# Display_Subsystem register map
Vendor: Texas Instruments
Peripheral module from a debugger description file (folder omap34xx).
Registers are 32-bit, read-only, reset 0x0 unless marked. A register's access mark holds for its fields unless they carry their own. Offsets are as the file gives them; lines under a group give offsets from that group; [hi:lo] are bit positions; {n}, {i} and the like mark numbered series; 'fields as' and 'values as' point back to an identical list; <NAME> marks a mode.

## Display_Subsystem
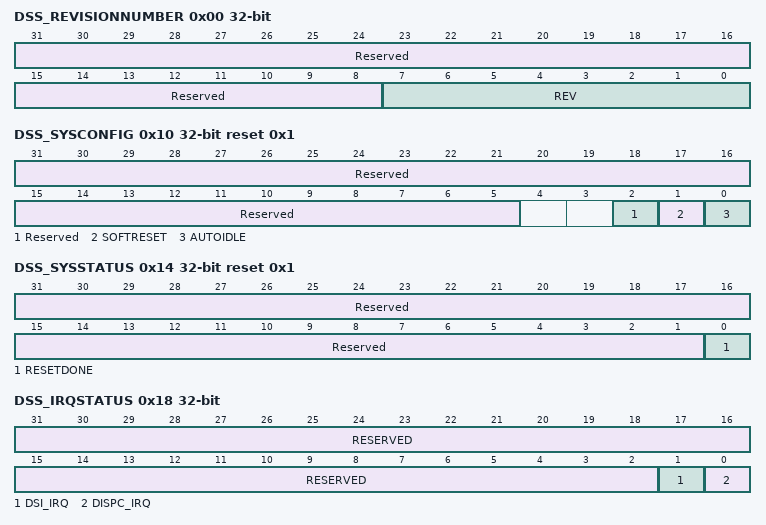
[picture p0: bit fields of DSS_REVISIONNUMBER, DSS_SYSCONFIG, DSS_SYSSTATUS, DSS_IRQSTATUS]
0x00 DSS_REVISIONNUMBER (reset mask 0xFFFFFF00) — This register contains the display subsystem revision number.
  [31:8] Reserved — Read returns 0.
  [7:0] REV — Revision number[7:4] Major revision[3:0] Minor revision
0x10 DSS_SYSCONFIG rw reset 0x1 — This register controls the various parameters of the interconnect interface.
  [31:5] Reserved — Write 0s for future compatibility. Reads return zero.
  [2] Reserved — Write 0s for future compatibility . Reads return zero.
  [1] SOFTRESET — Software reset. Set this bit to 1 to trigger a module reset. The bit is automatically reset by the hardware. During reads, it always returns 0.
    0=Normal mode; 1=The module is reset
  [0] AUTOIDLE — Enable power management capability
    0=OCP clock is free-running; 1=Automatic OCP clock gating strategy is applied based on the OCP interface activity
0x14 DSS_SYSSTATUS reset 0x1 — This register provides status information about the module.
  [31:1] Reserved — Read returns 0.
  [0] RESETDONE — Internal reset monitoring
    0=RESETDONE_0_r (Internal module reset is ongoing.); 1=RESETDONE_1_r (Reset completed)
0x18 DSS_IRQSTATUS — The register indicates the source of the interrupt and the status of the interrupt line.
  [31:2] RESERVED — Reads returns 0.
  [1] DSI_IRQ — DSI interrupt status (related toDSI_IRQSTATUS)
    0=DSI interrupt inactive; 1=DSI interrupt active
  [0] DISPC_IRQ — DISPC interrupt status (related toDISPC_IRQSTATUS)
    0=DISPC interrupt inactive; 1=DISPC interrupt active
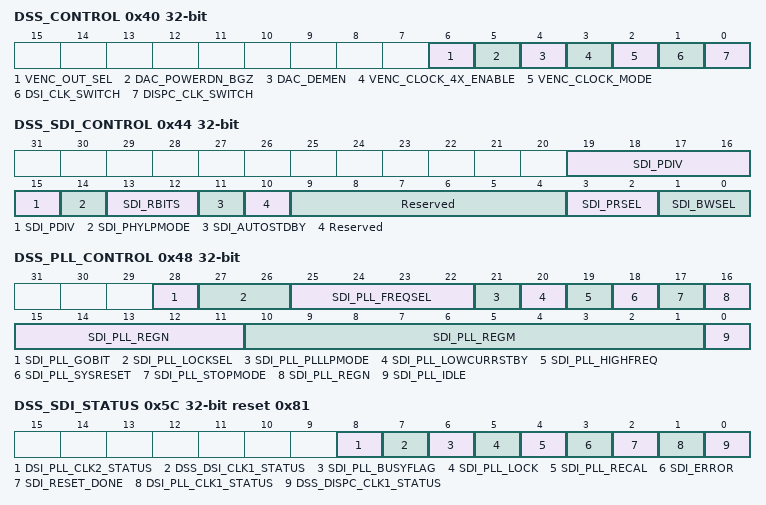
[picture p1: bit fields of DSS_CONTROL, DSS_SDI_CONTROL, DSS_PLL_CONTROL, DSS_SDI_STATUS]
0x40 DSS_CONTROL rw — This register contains the display subsystem control bits.
  [6] VENC_OUT_SEL — Video DAC1 input selection:0x0: CVBS VENC output selected for composite video mode0x1: Luminance VENC output selected for s-video mode
  [5] DAC_POWERDN_BGZ — DAC Power-Down Control0x0: DAC Power-Down Band Gap powered down0x1: DAC Power-Down Band Gap powered up
  [4] DAC_DEMEN — DAC dynamic element matching enable0x0: DAC Dynamic Element Matching Disabled 0x1: DAC Dynamic Element Matching Enabled
  [3] VENC_CLOCK_4X_ENABLE — VENC clock 4x enable0x0: Disable 0x1: Enable
  [2] VENC_CLOCK_MODE — VENC clock modeSee 0x0: Mode 0 All three balanced clocks, derived from DSS_TV_CLK, are provided to the VENC, if the VENC_CLOCK_4X_ENABLE [3] bit is set to 1 by software. 0x1: Mode 1 The VENC_CLOCK_4X_ENABLE [3] bit is used to control clock gating.
  [1] DSI_CLK_SWITCH — Selects the clock source for the DSI functional clock0x0: DSS1_ALWON_FCLK clock is selected (from PRCM)0x1: DSI2_PLL_FCLK clock is selected (from DSI PLL)
  [0] DISPC_CLK_SWITCH — Selects the clock source for the DISPC functional clock0x0: DSS1_ALWON_FCLK clock is selected (from PRCM)0x1: DSI1_PLL_FCLK clock is selected (from DSI PLL)
0x44 DSS_SDI_CONTROL rw — This register contains the display subsystem control bits.
  [19:15] SDI_PDIV — Specifies the ratio of PLL output to pixel clock frequency
  [14] SDI_PHYLPMODE — FlatLink3G output buffer low power optionDisables the internal transmitter termination to reduce power. Requires reduced data and signal integrity verification
    0=Standard mode; 1=Low-power mode
  [13:12] SDI_RBITS — FlatLink3G reserved bits F1 and F0
  [11] SDI_AUTOSTDBY — FlatLink3G auto-standby
    0=High-speed serial buffers only enabled when PLL is locked and SDI enable is active; 1=High-speed serial buffers enabled while SDI enable is active
  [10] Reserved — Must be programmed to the default value for SN65LVDS302 compatibility
  [9:4] Reserved — Must be programmed to the default value
  [3:2] SDI_PRSEL — Selection of the number of active data pairs
    0=1 pair: DATA0; 1=2 pairs: DATA0 and DATA1; 2=3 pairs: DATA0, DATA1, and DATA2
  [1:0] SDI_BWSEL — Selects the color depth: must be programmed to 0x2 for FlatLink3G
    2=Color depth is 24 bits
0x48 DSS_PLL_CONTROL rw — This register contains the display subsystem control bits.
  [28] SDI_PLL_GOBIT — Requests PLL locking sequence.See the programming guide section for the use of this bit in conjunction with DSS_STATUS[6] SDI_PLL_BUSYFLAG0: Inactive 1: Request PLL locking sequence
  [27:26] SDI_PLL_LOCKSEL — Selects the lock criteria for PLL
    0=Phase Lock (recommended setting for FlatLink3G); 1=Fine Phase Lock; 2=Frequency Lock
  [25:22] SDI_PLL_FREQSEL — PLL internal reference frequency (Fint) range selectionOthers: Reserved .
    3=0.75MHz to 1.0MHz; 4=1.0MHz to 1.25MHz; 5=1.25MHz to 1.5MHz; 6=1.5MHz to 1.75MHz; 7=1.75MHz to 2.1MHz; 11=7.5MHz to 10MHz; 12=10MHz to 12.5MHz; 13=12.5MHz to 15MHz; 14=15MHz to 17.5MHz; 15=17.5MHz to 21MHz
  [21] SDI_PLL_PLLLPMODE — Select the power/performance of the PLL
    0=Full performance, minimized jitter; 1=Reduced power, increased jitter
  [20] SDI_PLL_LOWCURRSTBY — PLL Low Current Standby
    0=Low Current Standby is not selected; 1=Low Current Standby is selected
  [19] SDI_PLL_HIGHFREQ — Enables a division of pixel clock by 2 before input of PLL.Required for pixel clock frequency above 32 MHz
    0=Pixel clock is not divided; 1=Pixel clock is divided by 2
  [18] SDI_PLL_SYSRESET — SDI PLL reset bit. Active low default0x0 : PLL under reset0x1 : PLL operational
  [17] SDI_PLL_STOPMODE — 0xSDI PLL STOPMODE0x0 : STOPMODE is not selected0x1 : STOPMODE is selected
  [16:11] SDI_PLL_REGN
  [10:1] SDI_PLL_REGM
  [0] SDI_PLL_IDLE
    0=IDLE is not selected; 1=IDLE is selected
0x5C DSS_SDI_STATUS reset 0x81 — This register contains the display subsystem register.
  [8] DSI_PLL_CLK2_STATUS — DSI2_PLL_FCLK clock selection status (DSI mux) Indicates if the DSI protocol engine is running from the DSI2_PLL_FCLK clockRead 0: DSI2_PLL_FCLK is not selected (unused by DSI).Read 1: DSI2_PLL_FCLK is selected (used by DSI).
  [7] DSS_DSI_CLK1_STATUS — DSS1_ALWON_FCLK clock selection status (DSI mux) Indicates if the DSI protocol engine is running from the DSS1_ALWON_FCLK clockRead 0: DSS1_ALWON_FCLK is not selected (unused by DSI).Read 1: DSS1_ALWON_FCLK is selected (used by DSI).
  [6] SDI_PLL_BUSYFLAG — PLL locking sequence status.See the programming guide section for the use of this bit in conjunction with DSS_PLL_CONTROL[28] SDI_PLL_GOBITRead 0: PLL lock request has completed.Read 1: PLL lock request is in progress.
  [5] SDI_PLL_LOCK — SDI PLL lock statusSee the programming guide section for the use of this bitRead 0: PLL is not lockedRead 1: PLL is locked
  [4] SDI_PLL_RECAL — SDI DPLL re-calibration statusIf this bit is active, the PLL must be recalibrated
    0=SDI_PLL_RECAL_0_r (Recalibration is not required.); 1=SDI_PLL_RECAL_1_r (Recalibration is required.)
  [3] SDI_ERROR — SDI error status bitSee programming guide section for error recovery procedureRead 0x0: No errorRead 0x1: Error condition required
  [2] SDI_RESET_DONE — SDI reset done statusThis status is delayed until the PLL output has started runningRead 0x0: SDI reset is in progressRead 0x1: SDI reset has completed
  [1] DSI_PLL_CLK1_STATUS — DSI1_PLL_FCLK clock selection status (DISPC mux) Indicates if the display controller is running from the DSI1_PLL_FCLK clockRead 0: DSI1_PLL_FCLK is not selected (unused by DISPC).Read 1: DSI1_PLL_FCLK is selected (used by DISPC).
  [0] DSS_DISPC_CLK1_STATUS — DSS1_ALWON_FCLK clock selection status (DISPC mux) Indicates if the display controller is running from the DSS1_ALWON_FCLK clockRead 0: DSS1_ALWON_FCLK is not selected (unused by DISPC).Read 1: DSS1_ALWON_FCLK is selected (used by DISPC).
